# STM32F105 register map
File version: 1.3
CPU: CM3 r1p1, little endian, no MPU, no FPU, 4 interrupt priority bits
Registers are 32-bit, read-write, reset 0x0 unless marked. A register's access mark holds for its fields unless they carry their own. Offsets are from the block's base; [hi:lo] are bit positions.

## SPI1 — Serial peripheral interface
Base 0x40013000
Same registers: SPI2 0x40003800, SPI3 0x40003C00
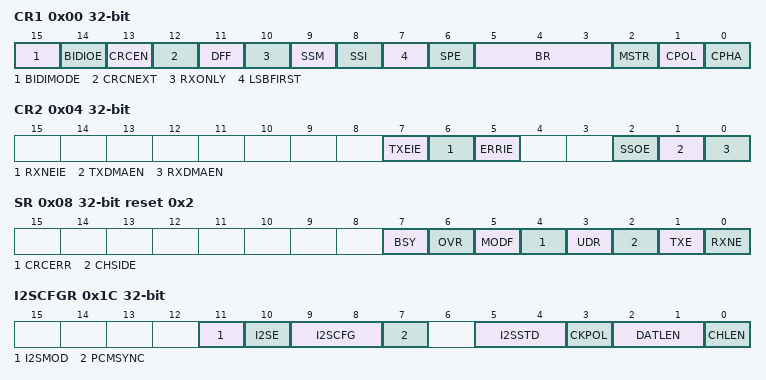
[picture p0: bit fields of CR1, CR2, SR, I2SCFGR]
0x00 CR1 — control register 1
  [15] BIDIMODE — Bidirectional data mode enable
  [14] BIDIOE — Output enable in bidirectional mode
  [13] CRCEN — Hardware CRC calculation enable
  [12] CRCNEXT — CRC transfer next
  [11] DFF — Data frame format
  [10] RXONLY — Receive only
  [9] SSM — Software slave management
  [8] SSI — Internal slave select
  [7] LSBFIRST — Frame format
  [6] SPE — SPI enable
  [5:3] BR — Baud rate control
  [2] MSTR — Master selection
  [1] CPOL — Clock polarity
  [0] CPHA — Clock phase
0x04 CR2 — control register 2
  [7] TXEIE — Tx buffer empty interrupt enable
  [6] RXNEIE — RX buffer not empty interrupt enable
  [5] ERRIE — Error interrupt enable
  [2] SSOE — SS output enable
  [1] TXDMAEN — Tx buffer DMA enable
  [0] RXDMAEN — Rx buffer DMA enable
0x08 SR access per field reset 0x2 — status register
  [7] BSY ro — Busy flag
  [6] OVR ro — Overrun flag
  [5] MODF ro — Mode fault
  [4] CRCERR rw — CRC error flag
  [3] UDR ro — Underrun flag
  [2] CHSIDE ro — Channel side
  [1] TXE ro — Transmit buffer empty
  [0] RXNE ro — Receive buffer not empty
0x0C DR — data register
  [15:0] DR — Data register
0x10 CRCPR reset 0x7 — CRC polynomial register
  [15:0] CRCPOLY
0x14 RXCRCR ro — RX CRC register
  [15:0] RxCRC
0x18 TXCRCR ro — TX CRC register
  [15:0] TxCRC
0x1C I2SCFGR — I2S configuration register
  [11] I2SMOD — I2S mode selection
  [10] I2SE — I2S Enable
  [9:8] I2SCFG — I2S configuration mode
  [7] PCMSYNC — PCM frame synchronization
  [5:4] I2SSTD — I2S standard selection
  [3] CKPOL — Steady state clock polarity
  [2:1] DATLEN — Data length to be transferred
  [0] CHLEN — Channel length (number of bits per audio channel)
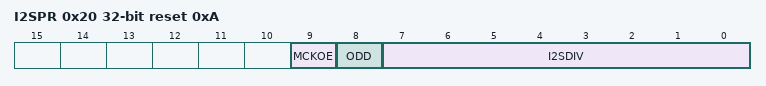
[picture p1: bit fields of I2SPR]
0x20 I2SPR reset 0xA — I2S prescaler register
  [9] MCKOE — Master clock output enable
  [8] ODD — Odd factor for the prescaler
  [7:0] I2SDIV — I2S Linear prescaler

## TIM6 — Basic timer
Base 0x40001000
Same registers: TIM7 0x40001400
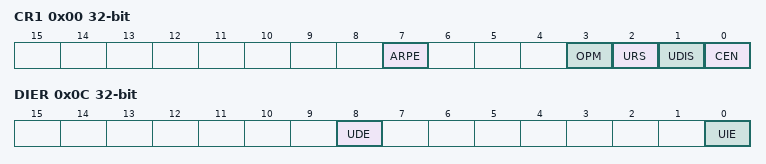
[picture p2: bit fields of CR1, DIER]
0x00 CR1 — control register 1
  [7] ARPE — Auto-reload preload enable
  [3] OPM — One-pulse mode
  [2] URS — Update request source
  [1] UDIS — Update disable
  [0] CEN — Counter enable
0x04 CR2 — control register 2
  [6:4] MMS — Master mode selection
0x0C DIER — DMA/Interrupt enable register
  [8] UDE — Update DMA request enable
  [0] UIE — Update interrupt enable
0x10 SR — status register
  [0] UIF — Update interrupt flag
0x14 EGR wo — event generation register
  [0] UG — Update generation
0x24 CNT — counter
  [15:0] CNT — Low counter value
0x28 PSC — prescaler
  [15:0] PSC — Prescaler value
0x2C ARR — auto-reload register
  [15:0] ARR — Low Auto-reload value

## USART1 — Universal synchronous asynchronous receiver transmitter
Base 0x40013800
Same registers: USART2 0x40004400, USART3 0x40004800
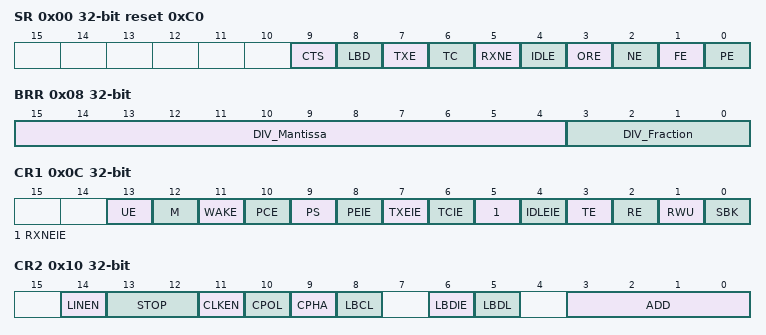
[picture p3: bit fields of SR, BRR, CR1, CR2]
0x00 SR access per field reset 0xC0 — Status register
  [9] CTS rw — CTS flag
  [8] LBD rw — LIN break detection flag
  [7] TXE ro — Transmit data register empty
  [6] TC rw — Transmission complete
  [5] RXNE rw — Read data register not empty
  [4] IDLE ro — IDLE line detected
  [3] ORE ro — Overrun error
  [2] NE ro — Noise error flag
  [1] FE ro — Framing error
  [0] PE ro — Parity error
0x04 DR — Data register
  [8:0] DR — Data value
0x08 BRR — Baud rate register
  [15:4] DIV_Mantissa — mantissa of USARTDIV
  [3:0] DIV_Fraction — fraction of USARTDIV
0x0C CR1 — Control register 1
  [13] UE — USART enable
  [12] M — Word length
  [11] WAKE — Wakeup method
  [10] PCE — Parity control enable
  [9] PS — Parity selection
  [8] PEIE — PE interrupt enable
  [7] TXEIE — TXE interrupt enable
  [6] TCIE — Transmission complete interrupt enable
  [5] RXNEIE — RXNE interrupt enable
  [4] IDLEIE — IDLE interrupt enable
  [3] TE — Transmitter enable
  [2] RE — Receiver enable
  [1] RWU — Receiver wakeup
  [0] SBK — Send break
0x10 CR2 — Control register 2
  [14] LINEN — LIN mode enable
  [13:12] STOP — STOP bits
  [11] CLKEN — Clock enable
  [10] CPOL — Clock polarity
  [9] CPHA — Clock phase
  [8] LBCL — Last bit clock pulse
  [6] LBDIE — LIN break detection interrupt enable
  [5] LBDL — lin break detection length
  [3:0] ADD — Address of the USART node
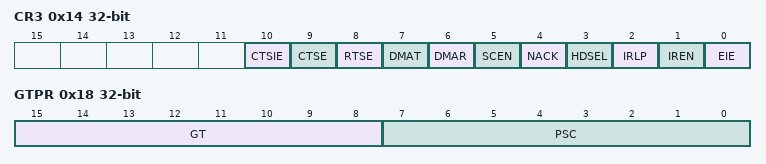
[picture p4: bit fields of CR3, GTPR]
0x14 CR3 — Control register 3
  [10] CTSIE — CTS interrupt enable
  [9] CTSE — CTS enable
  [8] RTSE — RTS enable
  [7] DMAT — DMA enable transmitter
  [6] DMAR — DMA enable receiver
  [5] SCEN — Smartcard mode enable
  [4] NACK — Smartcard NACK enable
  [3] HDSEL — Half-duplex selection
  [2] IRLP — IrDA low-power
  [1] IREN — IrDA mode enable
  [0] EIE — Error interrupt enable
0x18 GTPR — Guard time and prescaler register
  [15:8] GT — Guard time value
  [7:0] PSC — Prescaler value
